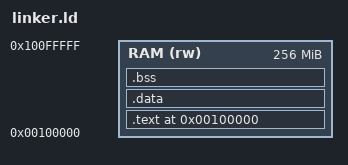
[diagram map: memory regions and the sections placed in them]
ENTRY(kernel_entry)

MEMORY
{
    RAM (rw) : ORIGIN = 0x100000, LENGTH = 256M
}

SECTIONS
{
    . = ORIGIN(RAM);

    .text :
    {
        *(.text*)
    } > RAM

    .data :
    {
        *(.data*)
    } > RAM

    .bss :
    {
        *(.bss*)
    } > RAM
}
